AUTOSAR XML (schema 00048)
package /SoftwareTypes/ComponentTypes
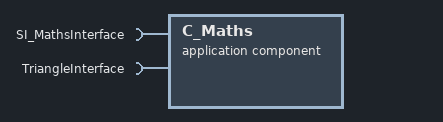
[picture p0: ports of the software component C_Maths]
  application sw component type C_Maths
    require port SI_MathsInterface: required-com-specs=[Add, Divide, Multiply, Substract], required-interface=SI_MathsInterface
    require port TriangleInterface: nonqueued-receiver-com-spec{data-element=Triangle, init-value=fields=0}, required-interface=TriangleInterface
    behavior C_Maths_ib: data-type-mapping=Data_Type_Mappings
